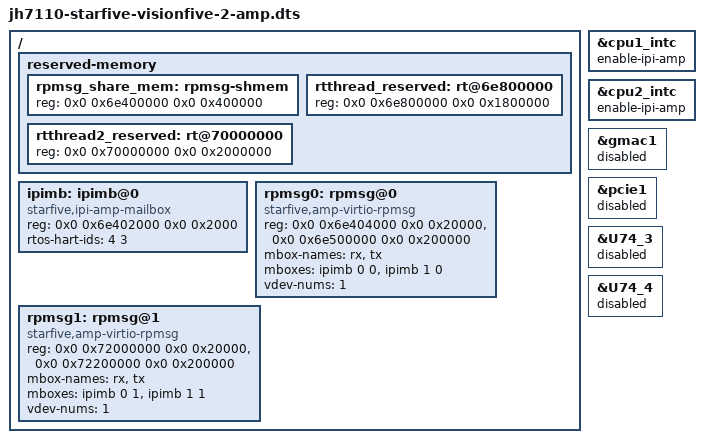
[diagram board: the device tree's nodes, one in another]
// SPDX-License-Identifier: GPL-2.0 OR MIT
/*
 * Copyright (C) 2022 StarFive Technology Co., Ltd.
 */

/dts-v1/;
#include "jh7110-starfive-visionfive-2-v1.3b.dts"

/ {
	reserved-memory {
		rpmsg_share_mem: rpmsg-shmem {
			reg = <0x0 0x6e400000 0x0 0x400000>;
		};

		rtthread_reserved: rt@6e800000 {
			reg = <0x0 0x6e800000 0x0 0x1800000>;
		};

		/* RT-Thread2 kernel + RPMSG channel */
		rtthread2_reserved: rt@70000000 {
			reg = <0x0 0x70000000 0x0 0x2000000>;
		};
	};

	ipimb: ipimb@0 {
		compatible = "starfive,ipi-amp-mailbox";
		reg = <0x0 0x6e402000 0x0 0x2000>;
		#mbox-cells = <2>;
		/* ch0: hart 4, ch1: hart 3 */
		rtos-hart-ids = <4 3>;
	};

	rpmsg0: rpmsg@0 {
		compatible = "starfive,amp-virtio-rpmsg";
		reg = <0x0 0x6e404000 0x0 0x20000>,
			<0x0 0x6e500000 0x0 0x200000>;
		mbox-names = "rx", "tx";
		mboxes = <&ipimb 0 0>, <&ipimb 1 0>;
		vdev-nums = <1>;
	};

	rpmsg1: rpmsg@1 {
		compatible = "starfive,amp-virtio-rpmsg";
		reg = <0x0 0x72000000 0x0 0x20000>,
		      <0x0 0x72200000 0x0 0x200000>;
		mbox-names = "rx", "tx";
		mboxes = <&ipimb 0 1>, <&ipimb 1 1>;
		vdev-nums = <1>;
	};
};

&cpu1_intc {
	enable-ipi-amp;
};

&cpu2_intc {
	enable-ipi-amp;
};

&gmac1 {
	status = "disabled";
};

&pcie1 {
	status = "disabled";
};

&U74_3 {
	status = "disabled";
};

&U74_4 {
	status = "disabled";
};
